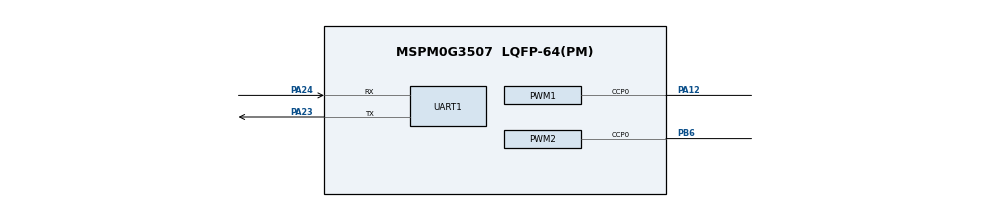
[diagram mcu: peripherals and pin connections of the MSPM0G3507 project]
/**
 * MSPM0G3507 dual stepper-motor configuration.
 * MCLK is generated by SYSPLL at 80 MHz.
 */
//@cliArgs --device "MSPM0G350X" --package "LQFP-64(PM)" --part "Default"
//@v2CliArgs --device "MSPM0G3507" --package "LQFP-64(PM)"
// @cliArgs --board /ti/boards/LP_MSPM0G3507 --rtos nortos

const GPIO   = scripting.addModule("/ti/driverlib/GPIO", {}, false);
const GPIO1  = GPIO.addInstance();
const PWM    = scripting.addModule("/ti/driverlib/PWM", {}, false);
const PWM1   = PWM.addInstance();
const PWM2   = PWM.addInstance();
const SYSCTL = scripting.addModule("/ti/driverlib/SYSCTL");
const UART   = scripting.addModule("/ti/driverlib/UART", {}, false);
const UART1  = UART.addInstance();

/*
 * 32 MHz SYSOSC -> SYSPLL -> 80 MHz HSCLK/MCLK.  These values are based on
 * TI's LP_MSPM0G3507 sysctl_mclk_syspll DriverLib example.
 */
const pllClk2xDivider       = system.clockTree["PLL_CLK2X_DIV"];
pllClk2xDivider.divideValue = 4;

const pllPDivider       = system.clockTree["PLL_PDIV"];
pllPDivider.divideValue = 2;

const ulpDivider       = system.clockTree["UDIV"];
ulpDivider.divideValue = 2;

const pllQMultiplier         = system.clockTree["PLL_QDIV"];
pllQMultiplier.multiplyValue = 10;

const hsclkMux       = system.clockTree["HSCLKMUX"];
hsclkMux.inputSelect = "HSCLKMUX_SYSPLL2X";

SYSCTL.MCLKSource            = "HSCLK";
SYSCTL.SYSPLL_CLK2XEn        = true;
SYSCTL.SYSPLL_CLK2XDiv       = 1;
SYSCTL.HSCLKSource           = "SYSPLLCLK2X";
SYSCTL.validateClkStatus     = true;
SYSCTL.SYSPLL_Qdiv           = 5;
SYSCTL.forceDefaultClkConfig = true;
SYSCTL.clockTreeEn           = true;

/* Direction and high-active enable outputs on the BoosterPack headers. */
GPIO1.$name                           = "MOTOR_DIR";
GPIO1.port                            = "PORTA";
GPIO1.associatedPins.create(4);
GPIO1.associatedPins[0].$name         = "MOTOR1_DIR";
GPIO1.associatedPins[0].assignedPin   = "16";
GPIO1.associatedPins[0].initialValue  = "CLEARED";
GPIO1.associatedPins[1].$name         = "MOTOR2_DIR";
GPIO1.associatedPins[1].assignedPin   = "17";
GPIO1.associatedPins[1].initialValue  = "CLEARED";
GPIO1.associatedPins[2].$name         = "MOTOR1_ENABLE";
GPIO1.associatedPins[2].assignedPin   = "18";
GPIO1.associatedPins[2].initialValue  = "CLEARED";
GPIO1.associatedPins[3].$name         = "MOTOR2_ENABLE";
GPIO1.associatedPins[3].assignedPin   = "15";
GPIO1.associatedPins[3].initialValue  = "CLEARED";

/*
 * Pitch and Yaw use independent timers so the tracking controller can command
 * a different step rate for each axis. Both timers run from 40 MHz ULPCLK / 8.
 */
PWM1.$name                       = "PITCH_PWM";
PWM1.timerCount                  = 3500;
PWM1.timerStartTimer             = false;
PWM1.clockDivider                = 8;
PWM1.ccIndex                     = [0];
PWM1.peripheral.$assign          = "TIMG0";
PWM1.peripheral.ccp0Pin.$assign  = "PA12";
PWM1.PWM_CHANNEL_0.$name         = "MOTOR1_STEP";
PWM1.PWM_CHANNEL_0.dutyCycle     = 1;
PWM1.PWM_CHANNEL_0.ccValue       = 3475;

PWM2.$name                       = "YAW_PWM";
PWM2.timerCount                  = 3500;
PWM2.timerStartTimer             = false;
PWM2.clockDivider                = 8;
PWM2.clockPrescale               = 2;
PWM2.ccIndex                     = [0];
PWM2.peripheral.$assign          = "TIMG6";
PWM2.peripheral.ccp0Pin.$assign  = "PB6";
PWM2.PWM_CHANNEL_0.$name         = "MOTOR2_STEP";
PWM2.PWM_CHANNEL_0.dutyCycle     = 1;
PWM2.PWM_CHANNEL_0.ccValue       = 3475;

/* Camera-board link: UART2, 230400 baud, 8 data bits, no parity, 1 stop bit. */
UART1.$name                            = "TRACKING_UART";
UART1.targetBaudRate                   = 230400;
UART1.enableFIFO                       = false;
UART1.enabledInterrupts                = ["RX","OVERRUN_ERROR","FRAMING_ERROR","PARITY_ERROR","NOISE_ERROR"];
UART1.peripheral.$assign               = "UART2";
UART1.peripheral.rxPin.$assign         = "PA24";
UART1.peripheral.txPin.$assign         = "PA23";

const Board = scripting.addModule("/ti/driverlib/Board", {}, false);
